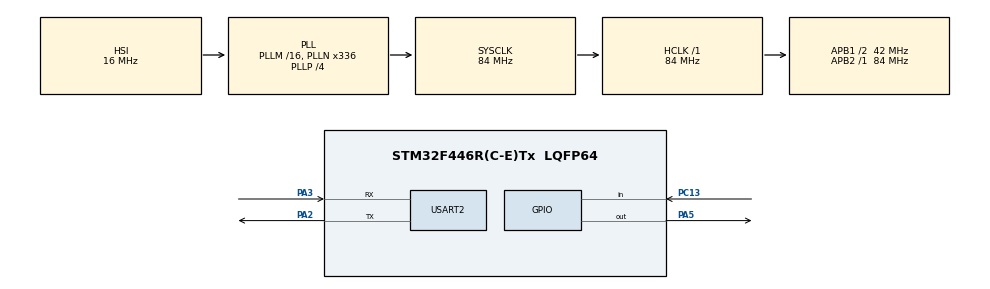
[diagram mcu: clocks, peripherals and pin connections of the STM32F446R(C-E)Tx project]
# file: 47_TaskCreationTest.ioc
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FREERTOS.Mutexes01=myMutex01,Dynamic,NULL
FREERTOS.Tasks01=defaultTask,24,128,StartDefaultTask,Default,NULL,Dynamic,NULL,NULL;myTask02,16,128,StartTask02,Default,NULL,Dynamic,NULL,NULL;myTask03,16,128,StartTask03,Default,NULL,Dynamic,NULL,NULL
Mcu.Family=STM32F4
Mcu.Name=STM32F446R(C-E)Tx
Mcu.Package=LQFP64
NVIC.PriorityGroup=NVIC_PRIORITYGROUP_4
NVIC.TIM3_IRQn=true\:15\:0\:false\:false\:true\:false\:false\:true\:true
NVIC.TimeBase=TIM3_IRQn
NVIC.TimeBaseIP=TIM3
PA2.Mode=Asynchronous
PA2.Signal=USART2_TX
PA3.Mode=Asynchronous
PA3.Signal=USART2_RX
PA5.Signal=GPIO_Output
PC13.Signal=GPIO_Input
ProjectManager.HeapSize=0x200
ProjectManager.StackSize=0x400
ProjectManager.TargetToolchain=STM32CubeIDE
RCC.AHBFreq_Value=84000000
RCC.APB1CLKDivider=RCC_HCLK_DIV2
RCC.APB1Freq_Value=42000000
RCC.APB1TimFreq_Value=84000000
RCC.APB2Freq_Value=84000000
RCC.APB2TimFreq_Value=84000000
RCC.CortexFreq_Value=84000000
RCC.FLatency-AdvancedSettings=FLASH_LATENCY_2
RCC.HCLKFreq_Value=84000000
RCC.HSE_VALUE=8000000
RCC.HSI_VALUE=16000000
RCC.LSE_VALUE=32768
RCC.PLLN=336
RCC.PLLP=RCC_PLLP_DIV4
RCC.SYSCLKFreq_VALUE=84000000
RCC.SYSCLKSource=RCC_SYSCLKSOURCE_PLLCLK
RCC.USBFreq_Value=168000000
RCC.VCOOutputFreq_Value=336000000
USART2.VirtualMode=VM_ASYNC
VP_FREERTOS_VS_CMSIS_V2.Mode=CMSIS_V2
VP_SYS_VS_tim3.Mode=TIM3
board=NUCLEO-F446RE

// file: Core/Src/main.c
/* USER CODE BEGIN Header */
/**
  ******************************************************************************
  * @file           : main.c
  * @brief          : Main program body
  ******************************************************************************
  * @attention
  *
  * Copyright (c) 2023 STMicroelectronics.
  * All rights reserved.
  *
  * This software is licensed under terms that can be found in the LICENSE file
  * in the root directory of this software component.
  * If no LICENSE file comes with this software, it is provided AS-IS.
  *
  ******************************************************************************
  */
/* USER CODE END Header */
#include "main.h"
#include "cmsis_os.h"

UART_HandleTypeDef huart2;

/* Definitions for defaultTask */
osThreadId_t defaultTaskHandle;
const osThreadAttr_t defaultTask_attributes = {
  .name = "defaultTask",
  .stack_size = 128 * 4,
  .priority = (osPriority_t) osPriorityNormal,
};
/* Definitions for myTask02 */
osThreadId_t myTask02Handle;
const osThreadAttr_t myTask02_attributes = {
  .name = "myTask02",
  .stack_size = 128 * 4,
  .priority = (osPriority_t) osPriorityBelowNormal,
};
/* Definitions for myTask03 */
osThreadId_t myTask03Handle;
const osThreadAttr_t myTask03_attributes = {
  .name = "myTask03",
  .stack_size = 128 * 4,
  .priority = (osPriority_t) osPriorityBelowNormal,
};
/* Definitions for myMutex01 */
osMutexId_t myMutex01Handle;
const osMutexAttr_t myMutex01_attributes = {
  .name = "myMutex01"
};

void SystemClock_Config(void);
static void MX_GPIO_Init(void);
static void MX_USART2_UART_Init(void);
void StartDefaultTask(void *argument);
void StartTask02(void *argument);
void StartTask03(void *argument);

int main(void)
{

  /* MCU Configuration--------------------------------------------------------*/

  /* Reset of all peripherals, Initializes the Flash interface and the Systick. */
  HAL_Init();

  /* Configure the system clock */
  SystemClock_Config();

  /* Initialize all configured peripherals */
  MX_GPIO_Init();
  MX_USART2_UART_Init();

  /* Init scheduler */
  osKernelInitialize();
  /* Create the mutex(es) */
  /* creation of myMutex01 */
  myMutex01Handle = osMutexNew(&myMutex01_attributes);

  /* Create the thread(s) */
  /* creation of defaultTask */
  defaultTaskHandle = osThreadNew(StartDefaultTask, NULL, &defaultTask_attributes);

  /* creation of myTask02 */
  myTask02Handle = osThreadNew(StartTask02, NULL, &myTask02_attributes);

  /* creation of myTask03 */
  myTask03Handle = osThreadNew(StartTask03, NULL, &myTask03_attributes);

  /* Start scheduler */
  osKernelStart();
  /* We should never get here as control is now taken by the scheduler */
  /* Infinite loop */
  while (1)
  {

  }
}

void SystemClock_Config(void)
{
  RCC_OscInitTypeDef RCC_OscInitStruct = {0};
  RCC_ClkInitTypeDef RCC_ClkInitStruct = {0};

  /** Configure the main internal regulator output voltage
  */
  __HAL_RCC_PWR_CLK_ENABLE();
  __HAL_PWR_VOLTAGESCALING_CONFIG(PWR_REGULATOR_VOLTAGE_SCALE3);

  /** Initializes the RCC Oscillators according to the specified parameters
  * in the RCC_OscInitTypeDef structure.
  */
  RCC_OscInitStruct.OscillatorType = RCC_OSCILLATORTYPE_HSI;
  RCC_OscInitStruct.HSIState = RCC_HSI_ON;
  RCC_OscInitStruct.HSICalibrationValue = RCC_HSICALIBRATION_DEFAULT;
  RCC_OscInitStruct.PLL.PLLState = RCC_PLL_ON;
  RCC_OscInitStruct.PLL.PLLSource = RCC_PLLSOURCE_HSI;
  RCC_OscInitStruct.PLL.PLLM = 16;
  RCC_OscInitStruct.PLL.PLLN = 336;
  RCC_OscInitStruct.PLL.PLLP = RCC_PLLP_DIV4;
  RCC_OscInitStruct.PLL.PLLQ = 2;
  RCC_OscInitStruct.PLL.PLLR = 2;
  if (HAL_RCC_OscConfig(&RCC_OscInitStruct) != HAL_OK)
  {
    Error_Handler();
  }

  /** Initializes the CPU, AHB and APB buses clocks
  */
  RCC_ClkInitStruct.ClockType = RCC_CLOCKTYPE_HCLK|RCC_CLOCKTYPE_SYSCLK
                              |RCC_CLOCKTYPE_PCLK1|RCC_CLOCKTYPE_PCLK2;
  RCC_ClkInitStruct.SYSCLKSource = RCC_SYSCLKSOURCE_PLLCLK;
  RCC_ClkInitStruct.AHBCLKDivider = RCC_SYSCLK_DIV1;
  RCC_ClkInitStruct.APB1CLKDivider = RCC_HCLK_DIV2;
  RCC_ClkInitStruct.APB2CLKDivider = RCC_HCLK_DIV1;

  if (HAL_RCC_ClockConfig(&RCC_ClkInitStruct, FLASH_LATENCY_2) != HAL_OK)
  {
    Error_Handler();
  }
}

static void MX_USART2_UART_Init(void)
{

  huart2.Instance = USART2;
  huart2.Init.BaudRate = 115200;
  huart2.Init.WordLength = UART_WORDLENGTH_8B;
  huart2.Init.StopBits = UART_STOPBITS_1;
  huart2.Init.Parity = UART_PARITY_NONE;
  huart2.Init.Mode = UART_MODE_TX_RX;
  huart2.Init.HwFlowCtl = UART_HWCONTROL_NONE;
  huart2.Init.OverSampling = UART_OVERSAMPLING_16;
  if (HAL_UART_Init(&huart2) != HAL_OK)
  {
    Error_Handler();
  }

}

static void MX_GPIO_Init(void)
{
  GPIO_InitTypeDef GPIO_InitStruct = {0};

  /* GPIO Ports Clock Enable */
  __HAL_RCC_GPIOC_CLK_ENABLE();
  __HAL_RCC_GPIOA_CLK_ENABLE();

  /*Configure GPIO pin Output Level */
  HAL_GPIO_WritePin(GPIOA, GPIO_PIN_5, GPIO_PIN_RESET);

  /*Configure GPIO pin : PC13 */
  GPIO_InitStruct.Pin = GPIO_PIN_13;
  GPIO_InitStruct.Mode = GPIO_MODE_INPUT;
  GPIO_InitStruct.Pull = GPIO_NOPULL;
  HAL_GPIO_Init(GPIOC, &GPIO_InitStruct);

  /*Configure GPIO pin : PA5 */
  GPIO_InitStruct.Pin = GPIO_PIN_5;
  GPIO_InitStruct.Mode = GPIO_MODE_OUTPUT_PP;
  GPIO_InitStruct.Pull = GPIO_NOPULL;
  GPIO_InitStruct.Speed = GPIO_SPEED_FREQ_LOW;
  HAL_GPIO_Init(GPIOA, &GPIO_InitStruct);

}

void StartDefaultTask(void *argument)
{
  for(;;)
  {
	 osDelay(1);
  }
}

void StartTask02(void *argument)
{
  /* USER CODE BEGIN StartTask02 */
  uint8_t message[] = "Greetings from thread1 \r\n";
  /* Infinite loop */
  for(;;)
  {
	// HAL_GPIO_TogglePin(GPIOA, GPIO_PIN_5);
	xSemaphoreTake(myMutex01Handle, portMAX_DELAY);
	HAL_UART_Transmit(&huart2, message, sizeof(message) - 1, 10);
	xSemaphoreGive(myMutex01Handle);
	osDelay(1);
  }
  /* USER CODE END StartTask02 */
}

void StartTask03(void *argument)
{
  /* USER CODE BEGIN StartTask03 */
  uint8_t message[] = "Greetings from thread2 \r\n";
  /* Infinite loop */
  for(;;)
  {
//	if(HAL_GPIO_ReadPin(GPIOC, GPIO_PIN_13) == GPIO_PIN_RESET)
//	{
//		HAL_UART_Transmit(&huart2, message, sizeof(message) - 1, 10);
//	}
	xSemaphoreTake(myMutex01Handle, portMAX_DELAY);
	HAL_UART_Transmit(&huart2, message, sizeof(message) - 1, 10);
	xSemaphoreGive(myMutex01Handle);
    osDelay(1);
  }
  /* USER CODE END StartTask03 */
}

void HAL_TIM_PeriodElapsedCallback(TIM_HandleTypeDef *htim)
{
  if (htim->Instance == TIM3) {
    HAL_IncTick();
  }
}

void Error_Handler(void)
{
  __disable_irq();
  while (1)
  {
  }
}
